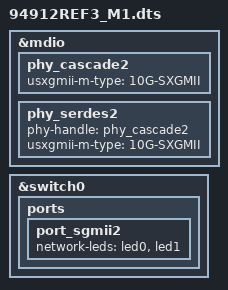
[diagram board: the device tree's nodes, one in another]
#include "94912REF3.dts"

&mdio {
    /* Port PHY mapping:
            port_gphy0 <----> phy_gphy0
            port_gphy1 <----> phy_gphy1
            port_gphy2 <----> phy_gphy2
            port_gphy3 <----> phy_gphy3
            port_xgphy <----> phy_serdes0   - phy_cascade0
            port_sgmii1 <---> phy_serdes1   - sfp0
            port_sgmii2 <---> phy_serdes2   - phy_cascade2
     */
	phy_cascade2 {
		status = "okay";
		usxgmii-m-type = "10G-SXGMII";  /* types: 10G-SXGMII 10G-DXGMII 10G-QXGMII 5G-SXGMII 5G-DXGMII 2.5G-SXGMII */
	};

	phy_serdes2 {
		phy-handle = <&phy_cascade2>;
		status = "okay";
		usxgmii-m-type = "10G-SXGMII";  /* types: 10G-SXGMII 10G-DXGMII 10G-QXGMII 5G-SXGMII 5G-DXGMII 2.5G-SXGMII */
	};
};

&switch0 {
	ports {
		port_sgmii2 {
			network-leds = <&led0 &led1>;
			status = "okay";
		};
	};
};
